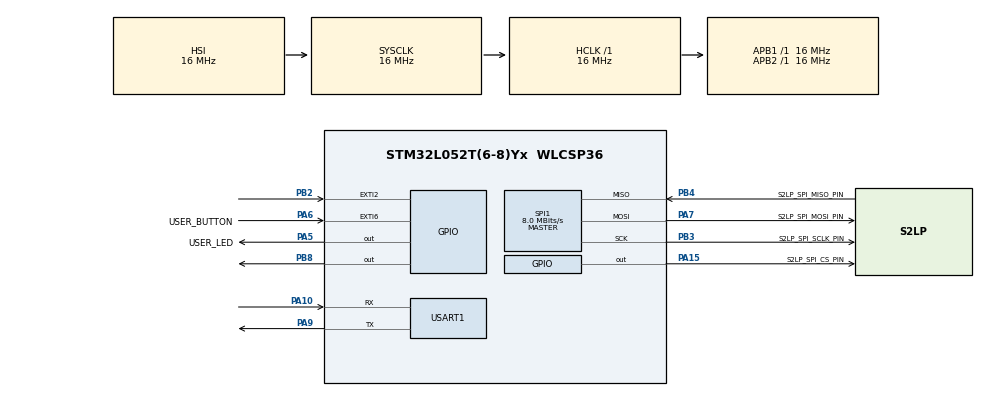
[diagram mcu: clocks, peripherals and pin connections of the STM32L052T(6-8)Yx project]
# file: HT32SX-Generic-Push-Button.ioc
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Mcu.Family=STM32L0
Dma.SPI1_TX.0.MemInc=DMA_MINC_ENABLE
Dma.SPI1_TX.0.PeriphInc=DMA_PINC_DISABLE
Dma.SPI1_RX.1.Mode=DMA_NORMAL
SPI1.VirtualType=VM_MASTER
Dma.USART1_TX.3.MemInc=DMA_MINC_ENABLE
Dma.USART1_TX.3.MemDataAlignment=DMA_MDATAALIGN_BYTE
Dma.USART1_RX.2.Instance=DMA1_Channel5
Dma.USART1_TX.3.Direction=DMA_MEMORY_TO_PERIPH
VP_RTC_VS_RTC_Activate.Mode=RTC_Enabled
PA6.GPIO_Label=USER_BUTTON
PB3.GPIO_Speed=GPIO_SPEED_FREQ_HIGH
RCC.SYSCLKSource=RCC_SYSCLKSOURCE_HSI
ProjectManager.StackSize=0x400
NVIC.RTC_IRQn=true\:1\:0\:true\:false\:true\:true\:true
PB2.GPIO_ModeDefaultEXTI=GPIO_MODE_IT_FALLING
PA15.GPIO_Label=S2LP_SPI_CS_PIN
TIM21.Period=50-1
RCC.PLLDIV=RCC_PLLDIV_4
Dma.SPI1_RX.1.PeriphInc=DMA_PINC_DISABLE
SPI1.Direction=SPI_DIRECTION_2LINES
RCC.HCLKFreq_Value=16000000
RCC.APB2TimFreq_Value=16000000
Dma.USART1_TX.3.Mode=DMA_NORMAL
SPI1.CalculateBaudRate=8.0 MBits/s
RCC.AHBFreq_Value=16000000
PB2.Signal=GPXTI2
PB3.Mode=Full_Duplex_Master
Dma.SPI1_RX.1.Priority=DMA_PRIORITY_HIGH
RCC.PLLMUL=RCC_PLLMUL_4
PA6.GPIO_PuPd=GPIO_PULLUP
PB3.GPIO_PuPd=GPIO_PULLUP
PB4.Mode=Full_Duplex_Master
PA14.Mode=Serial_Wire
Dma.USART1_TX.3.PeriphInc=DMA_PINC_DISABLE
Dma.SPI1_RX.1.Direction=DMA_PERIPH_TO_MEMORY
Dma.USART1_TX.3.Instance=DMA1_Channel4
Dma.SPI1_TX.0.Mode=DMA_NORMAL
Mcu.Package=WLCSP36
PA6.Signal=GPXTI6
PA10.Signal=USART1_RX
VP_RTC_VS_RTC_Calendar.Mode=RTC_Calendar
PA15.Signal=GPIO_Output
Dma.Request2=USART1_RX
Dma.Request1=SPI1_RX
RCC.APB1TimFreq_Value=16000000
Dma.Request3=USART1_TX
Dma.Request0=SPI1_TX
Dma.SPI1_RX.1.MemInc=DMA_MINC_ENABLE
NVIC.EXTI4_15_IRQn=true\:2\:0\:true\:false\:true\:true\:true
Dma.USART1_RX.2.MemDataAlignment=DMA_MDATAALIGN_BYTE
RCC.HSI48_VALUE=48000000
PB4.Signal=SPI1_MISO
PB3.GPIO_Label=S2LP_SPI_SCLK_PIN
Dma.SPI1_RX.1.Instance=DMA1_Channel2
RCC.MSI_VALUE=2097000
PA6.GPIO_ModeDefaultEXTI=GPIO_MODE_IT_FALLING
RTC.WakeUpCounter=1000
PA7.Mode=Full_Duplex_Master
PA10.Mode=Asynchronous
VP_ADC_TempSens_Input.Mode=IN-TempSens
Dma.SPI1_RX.1.MemDataAlignment=DMA_MDATAALIGN_BYTE
VP_ADC_Vref_Input.Mode=IN-Vrefint
TIM6.Prescaler=16-1
VP_TIM6_VS_ClockSourceINT.Mode=Enable_Timer
Dma.USART1_RX.2.PeriphInc=DMA_PINC_DISABLE
USART1.VirtualMode-Asynchronous=VM_ASYNC
PA13.Signal=SYS_SWDIO
RCC.HSI16_VALUE=16000000
PA9.Mode=Asynchronous
ProjectManager.TargetToolchain=STM32CubeIDE
Dma.USART1_RX.2.Mode=DMA_CIRCULAR
Dma.SPI1_TX.0.PeriphDataAlignment=DMA_PDATAALIGN_BYTE
Dma.SPI1_TX.0.Direction=DMA_MEMORY_TO_PERIPH
Dma.USART1_RX.2.PeriphDataAlignment=DMA_PDATAALIGN_BYTE
PA9.Signal=USART1_TX
Dma.USART1_TX.3.PeriphDataAlignment=DMA_PDATAALIGN_BYTE
PB4.GPIO_PuPd=GPIO_PULLUP
RCC.LSE_VALUE=32768
PA7.GPIO_PuPd=GPIO_PULLUP
PA5.Signal=GPIO_Output
board=custom
RCC.VCOOutputFreq_Value=64000000
PA7.GPIO_Speed=GPIO_SPEED_FREQ_HIGH
Dma.USART1_RX.2.Priority=DMA_PRIORITY_LOW
NVIC.EXTI2_3_IRQn=true\:0\:0\:false\:false\:true\:true\:true
PA15.PinState=GPIO_PIN_SET
PB4.GPIO_Speed=GPIO_SPEED_FREQ_HIGH
RCC.APB2Freq_Value=16000000
Dma.USART1_RX.2.Direction=DMA_PERIPH_TO_MEMORY
PB4.GPIO_Label=S2LP_SPI_MISO_PIN
VP_TIM21_VS_ClockSourceINT.Mode=Internal
NVIC.DMA1_Channel4_5_6_7_IRQn=true\:0\:0\:false\:false\:true\:false\:true
VP_TIM2_VS_ClockSourceINT.Mode=Internal
SPI1.Mode=SPI_MODE_MASTER
TIM21.Prescaler=16000-1
Dma.SPI1_TX.0.Instance=DMA1_Channel3
NVIC.TIM21_IRQn=true\:0\:0\:false\:false\:true\:true\:true
PA13.Mode=Serial_Wire
Mcu.Name=STM32L052T(6-8)Yx
Dma.USART1_RX.2.MemInc=DMA_MINC_ENABLE
Dma.USART1_TX.3.Priority=DMA_PRIORITY_HIGH
Dma.SPI1_RX.1.PeriphDataAlignment=DMA_PDATAALIGN_BYTE
PB3.Signal=SPI1_SCK
RCC.SYSCLKFreq_VALUE=16000000
PA7.GPIO_Label=S2LP_SPI_MOSI_PIN
PA5.GPIO_Label=USER_LED
PA15.GPIO_Speed=GPIO_SPEED_FREQ_HIGH
PA14.Signal=SYS_SWCLK
ProjectManager.HeapSize=0x200
Dma.SPI1_TX.0.MemDataAlignment=DMA_MDATAALIGN_BYTE
Dma.SPI1_TX.0.Priority=DMA_PRIORITY_HIGH
RCC.HSI_VALUE=16000000
VP_RTC_VS_RTC_WakeUp_intern.Mode=WakeUp
PA15.GPIO_PuPd=GPIO_PULLUP
NVIC.DMA1_Channel2_3_IRQn=true\:1\:0\:true\:false\:true\:false\:true
PB8.Signal=GPIO_Output
RCC.APB1Freq_Value=16000000
PB8.GPIO_Speed=GPIO_SPEED_FREQ_HIGH
NVIC.ADC1_COMP_IRQn=true\:2\:0\:true\:false\:true\:true\:true
PA7.Signal=SPI1_MOSI

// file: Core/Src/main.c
/* USER CODE BEGIN Header */
/**
  ******************************************************************************
  * @file           : main.c
  * @brief          : Main program body
  ******************************************************************************
  * @attention
  *
  * <h2><center>&copy; Copyright (c) 2021 STMicroelectronics.
  * All rights reserved.</center></h2>
  *
  * This software component is licensed by ST under BSD 3-Clause license,
  * the "License"; You may not use this file except in compliance with the
  * License. You may obtain a copy of the License at:
  *                        opensource.org/licenses/BSD-3-Clause
  *
  ******************************************************************************
  */
/* USER CODE END Header */

#include "main.h"
#include "adc.h"
#include "dma.h"
#include "rtc.h"
#include "spi.h"
#include "tim.h"
#include "usart.h"
#include "gpio.h"

#ifdef DOWNLINK_FLAG
static uint8_t downlink_request = 1;
#else
static uint8_t downlink_request = 0;
#endif

/* USER CODE BEGIN PM */
#define DS18B20_PORT GPIOB
#define DS18B20_PIN GPIO_PIN_10 /* PB10 */

//#define SigFox_ON

#define DS18B20_ON

//#define LM35_ON

/* USER CODE END PM */

void ST_Init(void);
void SystemClock_Config(void);
void delay(uint32_t us);
uint8_t DS18B20_Start(void);
uint8_t DS18B20_Read(void);
void DS18B20_Write (uint8_t data);
uint8_t temp_byte1;
uint8_t temp_byte2;
float TEMP;
uint16_t Temperature;
sfx_u8 customer_data[3];

int main(void)
{

  /* MCU Configuration--------------------------------------------------------*/

  /* Reset of all peripherals, Initializes the Flash interface and the Systick. */
  HAL_Init();

  /* Configure the system clock */
  SystemClock_Config();

  /* Initialize all configured peripherals */
  MX_GPIO_Init();
  MX_DMA_Init();
  MX_RTC_Init();
  MX_SPI1_Init();
  MX_USART1_UART_Init();
  MX_ADC_Init();
  MX_TIM2_Init();
  MX_TIM21_Init();
  MX_TIM6_Init();

  HAL_TIM_Base_Start(&htim6);

  mcuConfig();

  	/********** OPEN AND CONFIFIGURES SIGFOX LIBRARY IN RCZ2 *********************/
  	/********** IN ORDER TO OPEN OTHER RCZS, SEE SIGFOX_API.h **/
  	/********** BASICALLY CHANGES TO OTHER RC VALUE LIKE RCZ3 **/
#ifdef SigFox_ON
  HT_API_ConfigRegion(RCZ2);
#endif

  printf("Comece a cronometrar 10seg");
  delay(10000);
  printf("Fim dos 10 segundos");

  while (1)
  {
#ifdef DS18B20_ON
	  DS18B20_Start();
	  HAL_Delay (1);
	  DS18B20_Write (0xCC);  // skip ROM
	  DS18B20_Write (0x44);  // convert t
	  HAL_Delay (800);

	  DS18B20_Start();
	  HAL_Delay(1);
	  DS18B20_Write (0xCC);  // skip ROM
	  DS18B20_Write (0xBE);  // Read Scratch-pad

	  temp_byte1 = DS18B20_Read();
	  temp_byte2 = DS18B20_Read();
	  TEMP = (temp_byte2<<8)|temp_byte1;
	  TEMP = TEMP/16.0;
	  TEMP = TEMP * 10;
	  Temperature = (int)TEMP;
	  printf("%d x 10^-1", Temperature);
	  printf("\n");
#endif

#ifdef LM35_ON

#endif

#ifdef SigFox_ON
	  customer_data[0] = (int)(Temperature / 100);
	  customer_data[1] = (int)(Temperature / 10);
	  customer_data[2] = (int)(Temperature % 10);
	  HT_API_SendFrame();
#endif
  }
}

void SystemClock_Config(void)
{
  RCC_OscInitTypeDef RCC_OscInitStruct = {0};
  RCC_ClkInitTypeDef RCC_ClkInitStruct = {0};
  RCC_PeriphCLKInitTypeDef PeriphClkInit = {0};

  /** Configure the main internal regulator output voltage
  */
  __HAL_PWR_VOLTAGESCALING_CONFIG(PWR_REGULATOR_VOLTAGE_SCALE1);
  /** Initializes the CPU, AHB and APB busses clocks
  */
  RCC_OscInitStruct.OscillatorType = RCC_OSCILLATORTYPE_HSI|RCC_OSCILLATORTYPE_LSI;
  RCC_OscInitStruct.HSIState = RCC_HSI_ON;
  RCC_OscInitStruct.HSICalibrationValue = RCC_HSICALIBRATION_DEFAULT;
  RCC_OscInitStruct.LSIState = RCC_LSI_ON;
  RCC_OscInitStruct.PLL.PLLState = RCC_PLL_NONE;
  if (HAL_RCC_OscConfig(&RCC_OscInitStruct) != HAL_OK)
  {
    Error_Handler();
  }
  /** Initializes the CPU, AHB and APB busses clocks
  */
  RCC_ClkInitStruct.ClockType = RCC_CLOCKTYPE_HCLK|RCC_CLOCKTYPE_SYSCLK
                              |RCC_CLOCKTYPE_PCLK1|RCC_CLOCKTYPE_PCLK2;
  RCC_ClkInitStruct.SYSCLKSource = RCC_SYSCLKSOURCE_HSI;
  RCC_ClkInitStruct.AHBCLKDivider = RCC_SYSCLK_DIV1;
  RCC_ClkInitStruct.APB1CLKDivider = RCC_HCLK_DIV1;
  RCC_ClkInitStruct.APB2CLKDivider = RCC_HCLK_DIV1;

  if (HAL_RCC_ClockConfig(&RCC_ClkInitStruct, FLASH_LATENCY_0) != HAL_OK)
  {
    Error_Handler();
  }
  PeriphClkInit.PeriphClockSelection = RCC_PERIPHCLK_USART1|RCC_PERIPHCLK_RTC;
  PeriphClkInit.Usart1ClockSelection = RCC_USART1CLKSOURCE_PCLK2;
  PeriphClkInit.RTCClockSelection = RCC_RTCCLKSOURCE_LSI;
  if (HAL_RCCEx_PeriphCLKConfig(&PeriphClkInit) != HAL_OK)
  {
    Error_Handler();
  }
}

void HT_API_setSmpsVoltageAction(sfx_u8 mode) {
	ST_RF_API_smps(mode);
	printf("Set_smps_voltage %d\n", mode);
}

void HT_API_switchPa(uint8_t state) {

	ST_RF_API_set_pa(state);

	printf("Switch PA: %d\n", state);
}

void HT_API_ConfigRegion(rc_mask RCZ) {
	ST_SFX_ERR open_err = ST_SFX_ERR_NONE;

	switch(RCZ){
	case RCZ1:
		ST_RF_API_reduce_output_power(RCZ1_OUTPUT_POWER);
		open_err = St_Sigfox_Open_RCZ(RCZ1);
		HT_API_switchPa(0);
		HT_API_setSmpsVoltageAction(7);

		if(open_err != 0)
			printf("Open rcz error: %X\n", open_err);

		break;
	case RCZ2:
		ST_RF_API_reduce_output_power(RCZ2_OUTPUT_POWER);
		open_err = St_Sigfox_Open_RCZ(RCZ2);
		HT_API_switchPa(1);
		HT_API_setSmpsVoltageAction(2);

		if(open_err != 0)
			printf("Open rcz error: %X\n", open_err);

		break;
	case RCZ3:
		open_err = St_Sigfox_Open_RCZ(RCZ3);
		ST_RF_API_reduce_output_power(RCZ3_OUTPUT_POWER);
		HT_API_switchPa(0);
		HT_API_setSmpsVoltageAction(7);

		if(open_err != 0)
			printf("Open rcz error: %X\n", open_err);

		break;
	case RCZ4:
		open_err = St_Sigfox_Open_RCZ(RCZ4);
		ST_RF_API_reduce_output_power(RCZ4_OUTPUT_POWER);
		HT_API_switchPa(1);
		HT_API_setSmpsVoltageAction(2);

		if(open_err != 0)
			printf("Open rcz error: %X\n", open_err);

		break;
	case RCZ5:
		open_err = St_Sigfox_Open_RCZ(RCZ5);
		ST_RF_API_reduce_output_power(RCZ5_OUTPUT_POWER);
		HT_API_switchPa(0);
		HT_API_setSmpsVoltageAction(7);

		if(open_err != 0)
			printf("Open rcz error: %X\n", open_err);

		break;
	case RCZ6:
		open_err = St_Sigfox_Open_RCZ(RCZ6);
		ST_RF_API_reduce_output_power(RCZ6_OUTPUT_POWER);
		HT_API_switchPa(0);
		HT_API_setSmpsVoltageAction(7);

		if(open_err != 0)
			printf("Open rcz error: %X\n", open_err);

		break;
	case RCZ7:
		open_err = St_Sigfox_Open_RCZ(RCZ7);
		ST_RF_API_reduce_output_power(RCZ7_OUTPUT_POWER);
		HT_API_switchPa(0);
		HT_API_setSmpsVoltageAction(7);

		if(open_err != 0)
			printf("Open rcz error: %X\n", open_err);

		break;
	default:
		break;
	}

}

sfx_error_t HT_API_SendFrame(void) {

	/********** SEND MESSAGE TO RCZ2 ****************************/
	uint8_t customer_resp[8];
	sfx_error_t err;

#ifdef DOWNLINK_FLAG
	HAL_TIM_Base_Start_IT(&htim21);
#endif

	/********** FUNCTION PARAMETERS  ****************************/
	/********** THE LAST ONE IS TO REQUEST DOWNLINK ************/
	/********** 1 - YES, 0 - NO	 ******************************/

	err=SIGFOX_API_send_frame(customer_data,sizeof(customer_data),customer_resp, 3, downlink_request);

	if(downlink_request && !err) {
		printf("Customer resp: {");

		for(uint16_t i = 0; i < 7; i++)
			printf("0x%x,", customer_resp[i]);

		printf("0x%x}\n\r", customer_resp[7]);
	}

	printf("\nError Send Frame: %X\n", err);

#ifdef DOWNLINK_FLAG
	HAL_TIM_Base_Stop_IT(&htim21);
#endif

	return err;
}

void mcuConfig(void) {
	ST_SFX_ERR stSfxRetErr;

	ST_Init();

	NVM_BoardDataType sfxConfiguration;
	stSfxRetErr = ST_Sigfox_Init(&sfxConfiguration, 0);

	if(stSfxRetErr != ST_SFX_ERR_NONE) {
		if(stSfxRetErr == ST_SFX_ERR_CREDENTIALS) {
			sfxConfiguration.id = 0;
			memset(sfxConfiguration.pac, 0x00, 8);
			sfxConfiguration.rcz = 0;

		}
	}

	/* Calibrate RTC in case of STM32*/
	ST_MCU_API_TimerCalibration(500);

	printf("Sigfox iMCP HT32SX\n");

	printf("ID: %.8X - PAC: ", (unsigned int)sfxConfiguration.id);

	for(uint16_t i = 0; i < sizeof(sfxConfiguration.pac); i++)
	{
		printf("%.2X", sfxConfiguration.pac[i]);
	}

	printf("\n");

	/*			SET S2LP XTAL FREQUENCY														*/
	/*			DO NOT CHANGE IT																	*/

	ST_RF_API_set_xtal_freq(50000000);

	/*			SET A PROPER FREQUENCY OFFSET											*/
	/*			THIS VALUE CAN BE FOUND IN CREDENTIALS 						*/

	ST_RF_API_set_freq_offset(sfxConfiguration.freqOffset);
	printf("Freq Offset %ld \n", (int32_t)sfxConfiguration.freqOffset);

	/*			SET LBT OFFSET																		*/
	/*			THIS VALUE CAN BE FOUND IN CREDENTIALS 						*/

	ST_RF_API_set_lbt_thr_offset(sfxConfiguration.lbtOffset);
	printf("LBT %ld \n", (int32_t)sfxConfiguration.lbtOffset);

	/*			SET RSSI OFFSET																		*/
	/*			THIS VALUE CAN BE FOUND IN CREDENTIALS 						*/

	ST_RF_API_set_rssi_offset(sfxConfiguration.rssiOffset);
	printf("RSSI %ld \n", sfxConfiguration.rssiOffset);
}

void ST_Init(void) {
	/* Put the radio off */
	S2LPShutdownInit();
	HAL_Delay(10);
	S2LPShutdownExit();

	/* FEM Initialization */
	FEM_Init();
}

void Error_Handler(void)
{
/* User can add his own implementation to report the HAL error return state */
}

void delay(uint32_t us)
{
    __HAL_TIM_SET_COUNTER(&htim6,0);
    while ((__HAL_TIM_GET_COUNTER(&htim6))<us);
}

uint8_t DS18B20_Start (void)
{
	uint8_t Response = 0;
	Set_Pin_Output(DS18B20_PORT, DS18B20_PIN);   // set the pin as output
	HAL_GPIO_WritePin (DS18B20_PORT, DS18B20_PIN, 0);  // pull the pin low
	delay (480);   // delay according to datasheet

	Set_Pin_Input(DS18B20_PORT, DS18B20_PIN);    // set the pin as input
	delay (80);    // delay according to datasheet

	if (!(HAL_GPIO_ReadPin (DS18B20_PORT, DS18B20_PIN))) Response = 1;    // if the pin is low i.e the presence pulse is detected
	else Response = -1;

	delay (400); // 480 us delay totally.

	return Response;
}

void DS18B20_Write(uint8_t data)
{
	Set_Pin_Output(DS18B20_PORT, DS18B20_PIN);  // set as output

	for (int i=0; i<8; i++)
	{

		if ((data & (1<<i))!=0)  // if the bit is high
		{
			// write 1

			Set_Pin_Output(DS18B20_PORT, DS18B20_PIN);  // set as output
			HAL_GPIO_WritePin (DS18B20_PORT, DS18B20_PIN, 0);  // pull the pin LOW
			delay (1);  // wait for 1 us

			Set_Pin_Input(DS18B20_PORT, DS18B20_PIN);  // set as input
			delay (50);  // wait for 60 us
		}

		else  // if the bit is low
		{
			// write 0

			Set_Pin_Output(DS18B20_PORT, DS18B20_PIN);
			HAL_GPIO_WritePin (DS18B20_PORT, DS18B20_PIN, 0);  // pull the pin LOW
			delay (50);  // wait for 60 us

			Set_Pin_Input(DS18B20_PORT, DS18B20_PIN);
		}
	}
}

uint8_t DS18B20_Read(void)
{
	uint8_t value=0;
	Set_Pin_Input(DS18B20_PORT, DS18B20_PIN);

	for (int i=0;i<8;i++)
	{
		Set_Pin_Output(DS18B20_PORT, DS18B20_PIN);   // set as output

		HAL_GPIO_WritePin (DS18B20_PORT, DS18B20_PIN, 0);  // pull the data pin LOW
		delay (2);  // wait for 2 us

		Set_Pin_Input(DS18B20_PORT, DS18B20_PIN);  // set as input
		if (HAL_GPIO_ReadPin (DS18B20_PORT, DS18B20_PIN))  // if the pin is HIGH
		{
			value |= 1<<i;  // read = 1
		}
		delay (60);  // wait for 60 us
	}
	return value;
}
